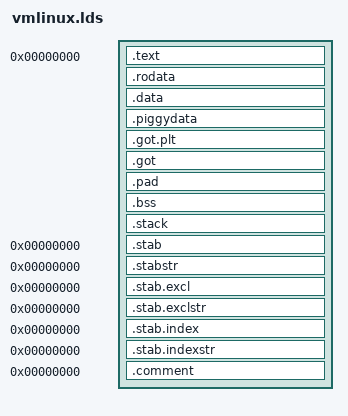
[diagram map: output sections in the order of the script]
/*
 *
 * Automatically generated file; DO NOT EDIT.
 * Linux/arm 4.9.84 Kernel Configuration
 *
 */
/*
 * The use of "&&" / "||" is limited in certain expressions.
 * The followings enable to calculate "and" / "or" with macro expansion only.
 */
/*
 * Helper macros to use CONFIG_ options in C/CPP expressions. Note that
 * these only work with boolean and tristate options.
 */
/*
 * Getting something that works in C and CPP for an arg that may or may
 * not be defined is tricky.  Here, if we have "#define CONFIG_BOOGER 1"
 * we match on the placeholder define, insert the "0," for arg1 and generate
 * the triplet (0, 1, 0).  Then the last step cherry picks the 2nd arg (a one).
 * When CONFIG_BOOGER is not defined, we generate a (... 1, 0) pair, and when
 * the last step cherry picks the 2nd arg, we get a zero.
 */
/*
 * IS_BUILTIN(CONFIG_FOO) evaluates to 1 if CONFIG_FOO is set to 'y', 0
 * otherwise. For boolean options, this is equivalent to
 * IS_ENABLED(CONFIG_FOO).
 */
/*
 * IS_MODULE(CONFIG_FOO) evaluates to 1 if CONFIG_FOO is set to 'm', 0
 * otherwise.
 */
/*
 * IS_REACHABLE(CONFIG_FOO) evaluates to 1 if the currently compiled
 * code can call a function defined in code compiled based on CONFIG_FOO.
 * This is similar to IS_ENABLED(), but returns false when invoked from
 * built-in code when CONFIG_FOO is set to 'm'.
 */
/*
 * IS_ENABLED(CONFIG_FOO) evaluates to 1 if CONFIG_FOO is set to 'y' or 'm',
 * 0 otherwise.
 */
/*
 *  Copyright (C) 2000 Russell King
 *
 * This program is free software; you can redistribute it and/or modify
 * it under the terms of the GNU General Public License version 2 as
 * published by the Free Software Foundation.
 */
OUTPUT_ARCH(arm)
ENTRY(_start)
SECTIONS
{
  /DISCARD/ : {
    *(.ARM.exidx*)
    *(.ARM.extab*)
    /*
     * Discard any r/w data - this produces a link error if we have any,
     * which is required for PIC decompression.  Local data generates
     * GOTOFF relocations, which prevents it being relocated independently
     * of the text/got segments.
     */
    *(.data)
  }
  . = 0;
  _text = .;
  .text : {
    _start = .;
    *(.start)
    *(.text)
    *(.text.*)
    *(.fixup)
    *(.gnu.warning)
    *(.glue_7t)
    *(.glue_7)
  }
  .rodata : {
    *(.rodata)
    *(.rodata.*)
  }
  .data : {
    /*
     * The EFI stub always executes from RAM, and runs strictly before the
     * decompressor, so we can make an exception for its r/w data, and keep it
     */
    *(.data.efistub)
  }
  .piggydata : {
    *(.piggydata)
  }
  . = ALIGN(4);
  _etext = .;
  .got.plt : { *(.got.plt) }
  _got_start = .;
  .got : { *(.got) }
  _got_end = .;
  /* ensure the zImage file size is always a multiple of 64 bits */
  /* (without a dummy byte, ld just ignores the empty section) */
  .pad : { BYTE(0); . = ALIGN(8); }
  _edata = .;
  _magic_sig = (0x016f2818);
  _magic_start = (_start);
  _magic_end = (_edata);
  . = ALIGN(8);
  __bss_start = .;
  .bss : { *(.bss) }
  _end = .;
  . = ALIGN(8); /* the stack must be 64-bit aligned */
  .stack : { *(.stack) }
  .stab 0 : { *(.stab) }
  .stabstr 0 : { *(.stabstr) }
  .stab.excl 0 : { *(.stab.excl) }
  .stab.exclstr 0 : { *(.stab.exclstr) }
  .stab.index 0 : { *(.stab.index) }
  .stab.indexstr 0 : { *(.stab.indexstr) }
  .comment 0 : { *(.comment) }
}
